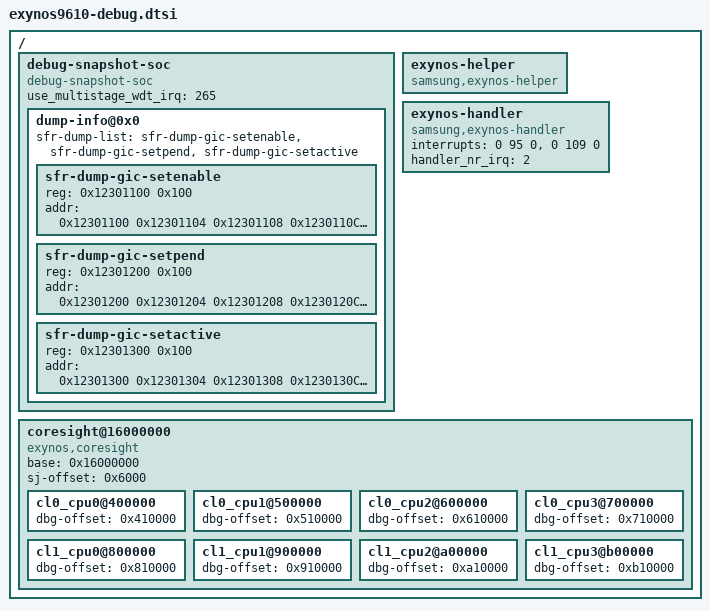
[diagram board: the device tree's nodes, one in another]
/*
 * SAMSUNG EXYNOS9820 SoC device tree source
 *
 * Copyright (c) 2018 Samsung Electronics Co., Ltd.
 *		http://www.samsung.com
 *
 * SAMSUNG EXYNOS9820 SoC device nodes are listed in this file.
 * EXYNOS9820 based board files can include this file and provide
 * values for board specfic bindings.
 *
 * This program is free software; you can redistribute it and/or modify
 * it under the terms of the GNU General Public License version 2 as
 * published by the Free Software Foundation.
 */

#include <dt-bindings/clock/exynos9610.h>

/ {
	debug-snapshot-soc {
		compatible = "debug-snapshot-soc";
		#address-cells = <1>;
		#size-cells = <1>;

		use_multistage_wdt_irq = <265>;
		dump-info@0x0 {
			sfr-dump-list = "sfr-dump-gic-setenable", "sfr-dump-gic-setpend", "sfr-dump-gic-setactive";
			#address-cells = <1>;
			#size-cells = <1>;

                        sfr-dump-gic-setenable {
                                reg = <0x12301100 0x100>;
                                addr = <0x12301100 0x12301104 0x12301108 0x1230110C
                                        0x12301110 0x12301114 0x12301118 0x1230111C
                                        0x12301120 0x12301124 0x12301128 0x1230112C
                                        0x12301130 0x12301134 0x12301138 0x1230113C
                                        0xFFFFFFFF>;
                        };

                        sfr-dump-gic-setpend {
                                reg = <0x12301200 0x100>;
                                addr = <0x12301200 0x12301204 0x12301208 0x1230120C
                                        0x12301210 0x12301214 0x12301218 0x1230121C
                                        0x12301220 0x12301224 0x12301228 0x1230122C
                                        0x12301230 0x12301234 0x12301238 0x1230123C
                                        0xFFFFFFFF>;
                        };

                        sfr-dump-gic-setactive {
                                reg = <0x12301300 0x100>;
                                addr = <0x12301300 0x12301304 0x12301308 0x1230130C
                                        0x12301310 0x12301314 0x12301318 0x1230131C
                                        0x12301320 0x12301324 0x12301328 0x1230132C
                                        0x12301330 0x12301334 0x12301338 0x1230133C
                                        0xFFFFFFFF>;
			};
		};
	};

	exynos-helper {
		compatible = "samsung,exynos-helper";
	};

	exynos-handler {
		compatible = "samsung,exynos-handler";
		interrupts =	<0 95 0>,	/* INTREQ__CPUCL0_nINTERRIRQ */
				<0 109 0>;	/* INTREQ__CPUCL1_nECCERRIRQ */
		handler_nr_irq = <2>;
	};

        coresight@16000000 {
		compatible = "exynos,coresight";
		base = <0x16000000>;
		sj-offset = <0x6000>;
		cl0_cpu0@400000 {
		        device_type = "cs";
			dbg-offset = <0x410000>;
		};
		cl0_cpu1@500000 {
		        device_type = "cs";
			dbg-offset = <0x510000>;
		};
		cl0_cpu2@600000 {
		        device_type = "cs";
			dbg-offset = <0x610000>;
		};
		cl0_cpu3@700000 {
		        device_type = "cs";
			dbg-offset = <0x710000>;
		};
		cl1_cpu0@800000 {
		        device_type = "cs";
			dbg-offset = <0x810000>;
		};
		cl1_cpu1@900000 {
		        device_type = "cs";
			dbg-offset = <0x910000>;
		};
		cl1_cpu2@a00000 {
		        device_type = "cs";
			dbg-offset = <0xa10000>;
		};
		cl1_cpu3@b00000 {
		        device_type = "cs";
			dbg-offset = <0xb10000>;
		};
	};
};
